# AUX_EVCTL register map
Vendor: Texas Instruments
Peripheral module from a debugger description file (folder CC2650).
Registers are 32-bit, access per field, reset 0x0 unless marked. A register's access mark holds for its fields unless they carry their own. Offsets are as the file gives them; lines under a group give offsets from that group; [hi:lo] are bit positions; {n}, {i} and the like mark numbered series; 'fields as' and 'values as' point back to an identical list; <NAME> marks a mode.

## AUX_EVCTL — AUX Event Controller
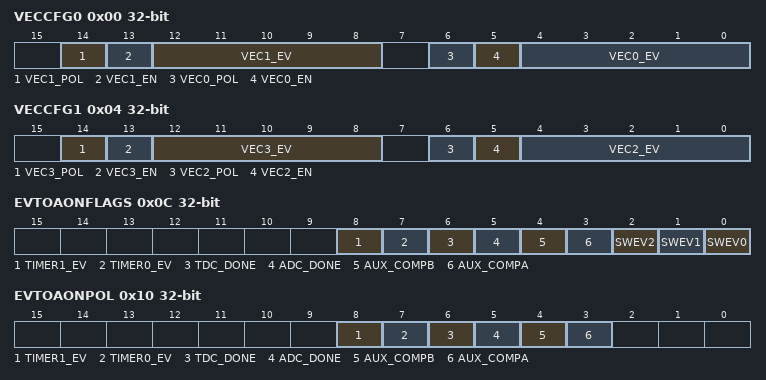
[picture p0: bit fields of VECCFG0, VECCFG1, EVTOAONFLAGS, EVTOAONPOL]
0x00 VECCFG0 — Vector Configuration 0 AUX_SCE event vectors 0 and 1 configuration
  [14] VEC1_POL rw — Selects vector 1 trigger event polarity. To manually trigger vector 1 execution, set VEC1_EV to a known static value, and toggle VEC1_POL twice.
    1=FALL (Falling edge triggers execution.); 0=RISE (Rising edge triggers execution.)
  [13] VEC1_EN rw — Enables (1) or disables (0) triggering of vector 1 execution. When enabled, the edge selected by VEC1_POL on the event selected by VEC1_EV will set VECFLAGS.VEC1, which in turn triggers vector 1 execution. Note: Lower vectors (0) have priority.
    1=EN (An event selected by VEC1_EV with polarity from VEC1_POL triggers a jump to vector # 1 when AUX_SCE is in sleep); 0=DIS (Event detection is disabled)
  [12:8] VEC1_EV rw — Selects vector 1 trigger source event.
    31=ADC_IRQ (ADC_IRQ event); 30=MCU_EV (MCU_EV event); 29=ACLK_REF (ACLK_REF event); {v}=AUXIO{v-13} (AUXIO{v-13} input data) (v=13..28); 12=AON_PROG_WU (AON_PROG_WU event); 11=AON_SW (AON_SW event); 10=OBSMUX1 (OBSMUX1 event); 9=OBSMUX0 (OBSMUX0 event); 8=ADC_FIFO_ALMOST_FULL (ADC_FIFO_ALMOST_FULL event); 7=ADC_DONE (ADC_DONE event); 6=SMPH_AUTOTAKE_DONE (SMPH_AUTOTAKE_DONE event); 5=TIMER1_EV (TIMER1_EV event); 4=TIMER0_EV (TIMER0_EV event); 3=TDC_DONE (TDC_DONE event); 2=AUX_COMPB (AUX_COMPB event); 1=AUX_COMPA (AUX_COMPA event); 0=AON_RTC_CH2 (AON_RTC_CH2 event)
  [6] VEC0_POL rw — Selects vector 0 trigger event polarity. To manually trigger vector 0 execution, set VEC0_EV to a known static value, and toggle VEC0_POL twice.
    values as VEC1_POL
  [5] VEC0_EN rw — Enables (1) or disables (0) triggering of vector 0 execution. When enabled, the edge selected by VEC0_POL on the event selected by VEC0_EV will set VECFLAGS.VEC0, which in turn triggers vector 0 execution.
    1=EN (An event selected by VEC0_EV with polarity from VEC0_POL triggers a jump to vector #0 when AUX_SCE is in sleep); 0=DIS (Event detection is disabled)
  [4:0] VEC0_EV rw — Selects vector 0 trigger source event.
    values as VEC1_EV
0x04 VECCFG1 — Vector Configuration 1 AUX_SCE event vectors 2 and 3 configuration
  [14] VEC3_POL rw — Selects vector 3 trigger event polarity. To manually trigger vector 3 execution, set VEC3_EV to a known static value, and toggle VEC3_POL twice.
    values as VECCFG0.VEC1_POL
  [13] VEC3_EN rw — Enables (1) or disables (0) triggering of vector 3 execution. When enabled, the edge selected by VEC3_POL on the event selected by VEC3_EV will set VECFLAGS.VEC3, which in turn triggers vector 3 execution. Note: Lower vectors (0, 1 and 2) have priority.
    1=EN (An event selected by VEC3_EV with polarity from VEC3_POL triggers a jump to vector # 3 when AUX_SCE is in sleep); 0=DIS (Event detection is disabled)
  [12:8] VEC3_EV rw — Selects vector 3 trigger source event.
    values as VECCFG0.VEC1_EV
  [6] VEC2_POL rw — Selects vector 2 trigger event polarity. To manually trigger vector 2 execution, set VEC2_EV to a known static value, and toggle VEC2_POL twice.
    values as VECCFG0.VEC1_POL
  [5] VEC2_EN rw — Enables (1) or disables (0) triggering of vector 2 execution. When enabled, the edge selected by VEC2_POL on the event selected by VEC2_EV will set VECFLAGS.VEC2, which in turn triggers vector 2 execution. Note: Lower vectors (0 and 1) have priority.
    1=EN (An event selected by VEC2_EV with polarity from VEC2_POL triggers a jump to vector # 2 when AUX_SCE is in sleep); 0=DIS (Event detection is disabled)
  [4:0] VEC2_EV rw — Selects vector 2 trigger source event.
    values as VECCFG0.VEC1_EV
0x08 SCEWEVSEL — Sensor Controller Engine Wait Event Selection Event selection for the AUX_SCE WEV0, WEV1, BEV0 and BEV1 instructions
  [4:0] WEV7_EV rw — Selects the event source to be mapped to AUX_SCE:WUSTAT.EV_SIGNALS bit 7.
    values as VECCFG0.VEC1_EV
0x0C EVTOAONFLAGS — Events To AON Domain Flags AUX event flags going to/through the AON domain These events may be used to wake up the MCU domain. The flags may be cleared by writing 0 to these bits or writing 1 to the corresponding bits in EVTOAONFLAGSCLR.
  [8] TIMER1_EV rw — TIMER1_EV event flag.
  [7] TIMER0_EV rw — TIMER0_EV event flag.
  [6] TDC_DONE rw — TDC_DONE event flag.
  [5] ADC_DONE rw — ADC_DONE event flag.
  [4] AUX_COMPB rw — AUX_COMPB event flag.
  [3] AUX_COMPA rw — AUX_COMPA event flag.
  [2] SWEV2 rw — SWEV2 event flag.
  [1] SWEV1 rw — SWEV1 event flag.
  [0] SWEV0 rw — SWEV0 event flag.
0x10 EVTOAONPOL — Events To AON Domain Polarity AUX event source polarity for the event flags going to/through the AON domain Note the inverse polarity (0 = high, 1 = low).
  [all] fields
    1=LOW (Low level); 0=HIGH (High level)
  [8] TIMER1_EV rw — Selects the event source level that sets EVTOAONFLAGS.TIMER1_EV.
  [7] TIMER0_EV rw — Selects the event source level that sets EVTOAONFLAGS.TIMER0_EV.
  [6] TDC_DONE rw — Selects the event source level that sets EVTOAONFLAGS.TDC_DONE.
  [5] ADC_DONE rw — Selects the event source level that sets EVTOAONFLAGS.ADC_DONE.
  [4] AUX_COMPB rw — Selects the event source level that sets EVTOAONFLAGS.AUX_COMPB.
  [3] AUX_COMPA rw — Selects the event source level that sets EVTOAONFLAGS.AUX_COMPA.
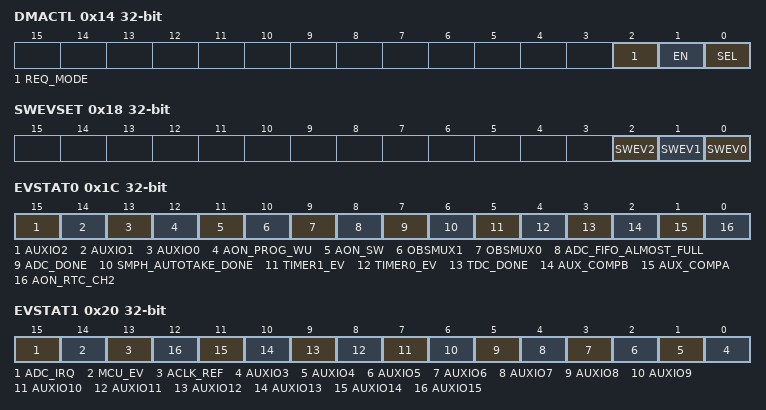
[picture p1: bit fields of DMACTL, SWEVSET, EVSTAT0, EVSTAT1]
0x14 DMACTL — Direct Memory Access Control
  [2] REQ_MODE rw — DMA Request mode
    1=SINGLE (Single requests are generated on DMA channel 7 when the condition configured in SEL is met); 0=BURST (Burst requests are generated on DMA channel 7 when the condition configured in SEL is met)
  [1] EN rw — 0: DMA interface is disabled 1: DMA interface is enabled
  [0] SEL rw — Selection of FIFO watermark level required to trigger an ADC_DMA transfer
    1=FIFO_ALMOST_FULL (ADC_DMA event will be generated when the ADC FIFO is almost full (3/4 full)); 0=FIFO_NOT_EMPTY (ADC_DMA event will be generated when there are valid samples in the ADC FIFO)
0x18 SWEVSET — Software Event Set Strobes for setting software events from the AUX domain to the AON/MCU Domains The use of these events is software-defined.
  [2] SWEV2 wo — Writing 1 sets software event 2. For the MCU domain, the event flag can be read from EVTOAONFLAGS.SWEV2 and cleared using EVTOAONFLAGSCLR.SWEV2.
  [1] SWEV1 wo — Writing 1 sets software event 1. For the MCU domain, the event flag can be read from EVTOAONFLAGS.SWEV1 and cleared using EVTOAONFLAGSCLR.SWEV1.
  [0] SWEV0 wo — Writing 1 sets software event 0. For the MCU domain, the event flag can be read from EVTOAONFLAGS.SWEV0 and cleared using EVTOAONFLAGSCLR.SWEV0.
0x1C EVSTAT0 ro — Event Status 0 Current event source levels, 15:0
  [15] AUXIO2 — Current value of AUXIO2 input data line
  [14] AUXIO1 — Current value of AUXIO1 input data line
  [13] AUXIO0 — Current value of AUXIO0 input data line
  [12] AON_PROG_WU — Current value of OBSMUX3 event line
  [11] AON_SW — Current value of OBSMUX2 event line
  [10] OBSMUX1 — Current value of OBSMUX1 event line
  [9] OBSMUX0 — Current value of OBSMUX0 event line
  [8] ADC_FIFO_ALMOST_FULL — Current value of ADC_FIFO_ALMOST_FULL event line
  [7] ADC_DONE — Current value of ADC_DONE event line
  [6] SMPH_AUTOTAKE_DONE — Current value of SMPH_AUTOTAKE_DONE event line
  [5] TIMER1_EV — Current value of TIMER1_EV event line
  [4] TIMER0_EV — Current value of TIMER0_EV event line
  [3] TDC_DONE — Current value of TDC_DONE event line
  [2] AUX_COMPB — Current value of AUX_COMPB event line
  [1] AUX_COMPA — Current value of AUX_COMPA event line
  [0] AON_RTC_CH2 — Current value of AON_RTC_CH2 event line
0x20 EVSTAT1 ro — Event Status 1 Current event source levels, 31:16
  [15] ADC_IRQ — Current value of ADC_IRQ event line
  [14] MCU_EV — Current value of MCU_EV event line
  [13] ACLK_REF — Current value of ACLK_REF event line
  [n-3] AUXIO{n} (n=3..15) — Current value of AUXIO{n} input data line
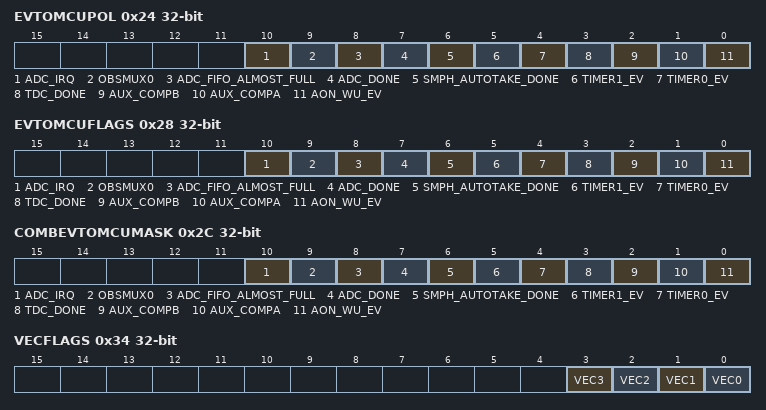
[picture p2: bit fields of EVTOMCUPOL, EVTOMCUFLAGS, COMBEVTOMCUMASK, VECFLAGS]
0x24 EVTOMCUPOL — Event To MCU Domain Polarity AUX event source polarity for the event flags to the MCU domain Note the inverse polarity (0 = high, 1 = low).
  [all] fields
    1=LOW (Low level); 0=HIGH (High level)
  [10] ADC_IRQ rw — Selects the event source level that sets EVTOMCUFLAGS.ADC_IRQ.
  [9] OBSMUX0 rw — Selects the event source level that sets EVTOMCUFLAGS.OBSMUX0.
  [8] ADC_FIFO_ALMOST_FULL rw — Selects the event source level that sets EVTOMCUFLAGS.ADC_FIFO_ALMOST_FULL.
  [7] ADC_DONE rw — Selects the event source level that sets EVTOMCUFLAGS.ADC_DONE.
  [6] SMPH_AUTOTAKE_DONE rw — Selects the event source level that sets EVTOMCUFLAGS.SMPH_AUTOTAKE_DONE.
  [5] TIMER1_EV rw — Selects the event source level that sets EVTOMCUFLAGS.TIMER1_EV.
  [4] TIMER0_EV rw — Selects the event source level that sets EVTOMCUFLAGS.TIMER0_EV.
  [3] TDC_DONE rw — Selects the event source level that sets EVTOMCUFLAGS.TDC_DONE.
  [2] AUX_COMPB rw — Selects the event source level that sets EVTOMCUFLAGS.AUX_COMPB.
  [1] AUX_COMPA rw — Selects the event source level that sets EVTOMCUFLAGS.AUX_COMPA.
  [0] AON_WU_EV rw — Selects the event source level that sets EVTOMCUFLAGS.AON_WU_EV
0x28 EVTOMCUFLAGS — Events to MCU Domain Flags AUX event flags going to the MCU domain The flags may be cleared by writing 0 to these bits or writing 1 to the corresponding bits in EVTOMCUFLAGSCLR.
  [10] ADC_IRQ rw — ADC_IRQ event flag.
  [9] OBSMUX0 rw — OBSMUX0 event flag.
  [8] ADC_FIFO_ALMOST_FULL rw — ADC_FIFO_ALMOST_FULL event flag.
  [7] ADC_DONE rw — ADC_DONE event flag.
  [6] SMPH_AUTOTAKE_DONE rw — SMPH_AUTOTAKE_DONE event flag.
  [5] TIMER1_EV rw — TIMER1_EV event flag.
  [4] TIMER0_EV rw — TIMER0_EV event flag.
  [3] TDC_DONE rw — TDC_DONE event flag.
  [2] AUX_COMPB rw — AUX_COMPB event flag.
  [1] AUX_COMPA rw — AUX_COMPA event flag.
  [0] AON_WU_EV rw — AON_WU_EV event flag. This is an OR of the AON_RTC_CH2, AON_PROG_WU and AON_SW events. These event sources must be cleared before clearing AON_WU_EV.
0x2C COMBEVTOMCUMASK — Combined Event To MCU Domain Mask Selects which of the flags In EVTOMCUFLAGS that contribute to the AUX_COMB event to the MCU domain The AUX_COMB event is asserted as long as one or more of the included event flags are set.
  [10] ADC_IRQ rw — Includes (1) or excludes (0) EVTOMCUFLAGS.ADC_IRQ contribution to the AUX_COMB event.
  [9] OBSMUX0 rw — Includes (1) or excludes (0) EVTOMCUFLAGS.OBSMUX0 contribution to the AUX_COMB event.
  [8] ADC_FIFO_ALMOST_FULL rw — Includes (1) or excludes (0) EVTOMCUFLAGS.ADC_FIFO_ALMOST_FULL contribution to the AUX_COMB event.
  [7] ADC_DONE rw — Includes (1) or excludes (0) EVTOMCUFLAGS.ADC_DONE contribution to the AUX_COMB event.
  [6] SMPH_AUTOTAKE_DONE rw — Includes (1) or excludes (0) EVTOMCUFLAGS.SMPH_AUTOTAKE_DONE contribution to the AUX_COMB event.
  [5] TIMER1_EV rw — Includes (1) or excludes (0) EVTOMCUFLAGS.TIMER1_EV contribution to the AUX_COMB event.
  [4] TIMER0_EV rw — Includes (1) or excludes (0) EVTOMCUFLAGS.TIMER0_EV contribution to the AUX_COMB event.
  [3] TDC_DONE rw — Includes (1) or excludes (0) EVTOMCUFLAGS.TDC_DONE contribution to the AUX_COMB event.
  [2] AUX_COMPB rw — Includes (1) or excludes (0) EVTOMCUFLAGS.AUX_COMPB contribution to the AUX_COMB event.
  [1] AUX_COMPA rw — Includes (1) or excludes (0) EVTOMCUFLAGS.AUX_COMPA contribution to the AUX_COMB event.
  [0] AON_WU_EV rw — Includes (1) or excludes (0) EVTOMCUFLAGS.AON_WU_EV contribution to the AUX_COMB event.
0x34 VECFLAGS — Vector Flags If a vector flag has been set and AUX_SCE is sleeping, it will wake up and execute the vector. If multiple vectors have been set, the one with the lowest index will execute first, and the next after returning to sleep. During execution of a vector, the flag must be cleared, by writing a 1 to the corresponding bit in VECFLAGSCLR.
  [3] VEC3 rw — The vector flag is set if the edge selected VECCFG1.VEC3_POL occurs on the event selected in VECCFG1.VEC3_EV. The flag is cleared by writing a 0 to this bit, or (preferably) a 1 to VECFLAGSCLR.VEC3.
  [2] VEC2 rw — The vector flag is set if the edge selected VECCFG1.VEC2_POL occurs on the event selected in VECCFG1.VEC2_EV. The flag is cleared by writing a 0 to this bit, or (preferably) a 1 to VECFLAGSCLR.VEC2.
  [1] VEC1 rw — The vector flag is set if the edge selected VECCFG0.VEC1_POL occurs on the event selected in VECCFG0.VEC1_EV. The flag is cleared by writing a 0 to this bit, or (preferably) a 1 to VECFLAGSCLR.VEC1.
  [0] VEC0 rw — The vector flag is set if the edge selected VECCFG0.VEC0_POL occurs on the event selected in VECCFG0.VEC0_EV. The flag is cleared by writing a 0 to this bit, or (preferably) a 1 to VECFLAGSCLR.VEC0.
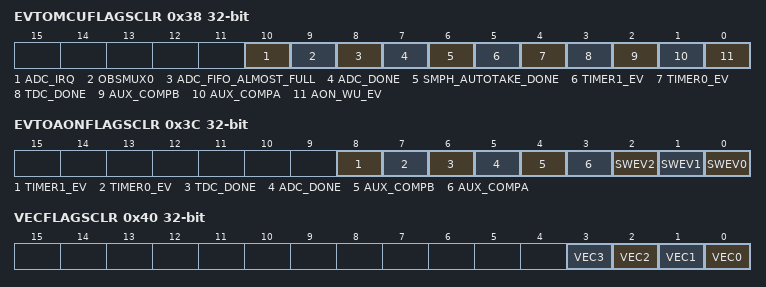
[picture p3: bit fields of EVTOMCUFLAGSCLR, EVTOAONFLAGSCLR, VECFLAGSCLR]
0x38 EVTOMCUFLAGSCLR — Events To MCU Domain Flags Clear Strobes for clearing flags in EVTOMCUFLAGS.
  [10] ADC_IRQ wo — Writing 1 clears EVTOMCUFLAGS.ADC_IRQ. Read value is 0.
  [9] OBSMUX0 wo — Writing 1 clears EVTOMCUFLAGS.OBSMUX0. Read value is 0.
  [8] ADC_FIFO_ALMOST_FULL wo — Writing 1 clears EVTOMCUFLAGS.ADC_FIFO_ALMOST_FULL. Read value is 0.
  [7] ADC_DONE wo — Writing 1 clears EVTOMCUFLAGS.ADC_DONE. Read value is 0.
  [6] SMPH_AUTOTAKE_DONE wo — Writing 1 clears [EVTOMCUFLAGS.SMPH_AUTOTAKE_DONE. Read value is 0.
  [5] TIMER1_EV wo — Writing 1 clears EVTOMCUFLAGS.TIMER1_EV. Read value is 0.
  [4] TIMER0_EV wo — Writing 1 clears EVTOMCUFLAGS.TIMER0_EV. Read value is 0.
  [3] TDC_DONE wo — Writing 1 clears EVTOMCUFLAGS.TDC_DONE. Read value is 0.
  [2] AUX_COMPB wo — Writing 1 clears EVTOMCUFLAGS.AUX_COMPB. Read value is 0.
  [1] AUX_COMPA wo — Writing 1 clears EVTOMCUFLAGS.AUX_COMPA. Read value is 0.
  [0] AON_WU_EV wo — Writing 1 clears EVTOMCUFLAGS.AON_WU_EV. Read value is 0.
0x3C EVTOAONFLAGSCLR — Events To AON Domain Clear Strobes for clearing flags in EVTOAONFLAGS.
  [8] TIMER1_EV wo — Writing 1 clears EVTOAONFLAGS.TIMER1_EV. Read value is 0.
  [7] TIMER0_EV wo — Writing 1 clears EVTOAONFLAGS.TIMER0_EV. Read value is 0.
  [6] TDC_DONE wo — Writing 1 clears EVTOAONFLAGS.TDC_DONE. Read value is 0.
  [5] ADC_DONE wo — Writing 1 clears EVTOAONFLAGS.ADC_DONE. Read value is 0.
  [4] AUX_COMPB wo — Writing 1 clears EVTOAONFLAGS.AUX_COMPB. Read value is 0.
  [3] AUX_COMPA wo — Writing 1 clears EVTOAONFLAGS.AUX_COMPA. Read value is 0.
  [2] SWEV2 wo — Writing 1 clears EVTOAONFLAGS.SWEV2. Read value is 0.
  [1] SWEV1 wo — Writing 1 clears EVTOAONFLAGS.SWEV1. Read value is 0.
  [0] SWEV0 wo — Writing 1 clears EVTOAONFLAGS.SWEV0. Read value is 0.
0x40 VECFLAGSCLR — Vector Flags Clear Strobes for clearing flags in VECFLAGS.
  [n] VEC{n} wo (n=0..3) — Writing 1 clears VECFLAGS.VEC{n}. Read value is 0.
